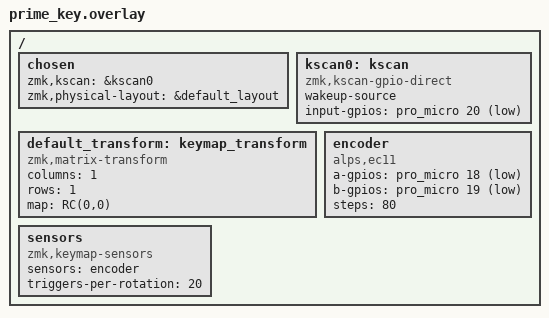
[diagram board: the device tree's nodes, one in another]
#include <dt-bindings/zmk/matrix_transform.h>
#include "prime_key-layouts.dtsi"

/ {
    chosen {
        zmk,kscan = &kscan0;
        zmk,physical-layout = &default_layout;
    };

    kscan0: kscan {
        compatible = "zmk,kscan-gpio-direct";
        wakeup-source;
        input-gpios = <&pro_micro 20 (GPIO_ACTIVE_LOW | GPIO_PULL_UP)>;
    };

    default_transform: keymap_transform {
        compatible = "zmk,matrix-transform";
        columns = <1>;
        rows = <1>;
        map = <RC(0,0)>;
    };

    encoder: encoder {
        compatible = "alps,ec11";
        a-gpios = <&pro_micro 18 (GPIO_ACTIVE_LOW | GPIO_PULL_UP)>;
        b-gpios = <&pro_micro 19 (GPIO_ACTIVE_LOW | GPIO_PULL_UP)>;
        steps = <80>;
        status = "okay";
    };

    sensors: sensors {
        compatible = "zmk,keymap-sensors";
        sensors = <&encoder>;
        triggers-per-rotation = <20>;
    };
};
